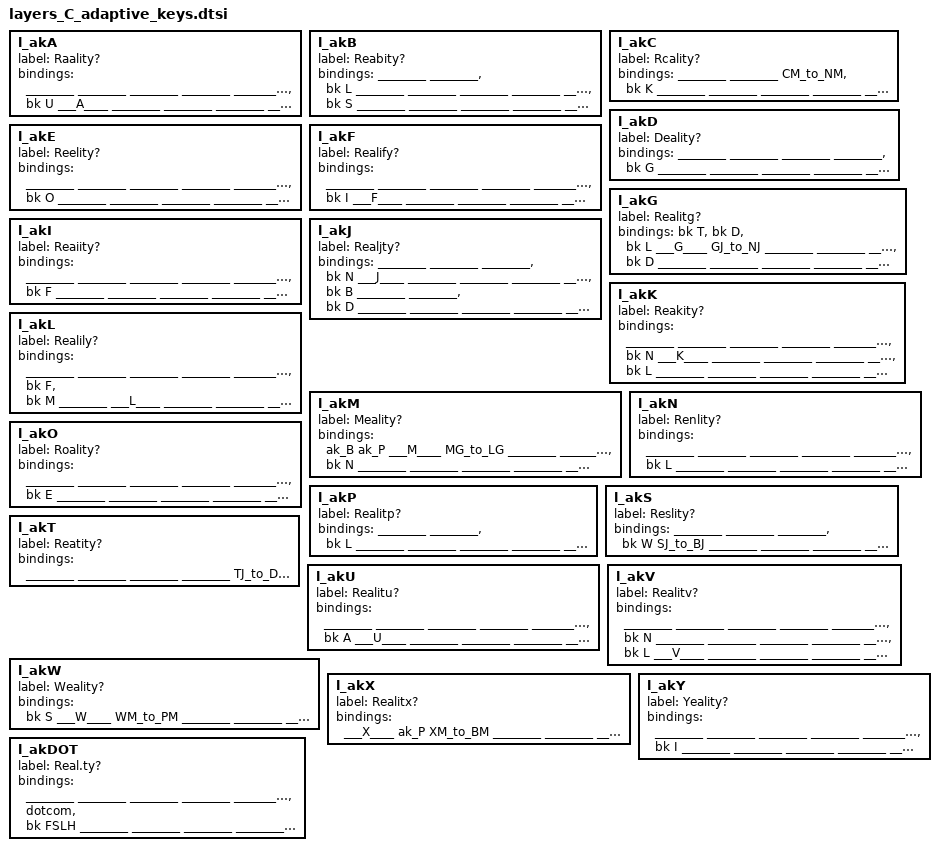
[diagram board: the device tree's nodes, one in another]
                l_akA {
                        label = "Raality?";
                        bindings = <
________   ________   ________   ________   ________          ________   ________   ________   ________   ________
________   ________   ________   ________   ________          &bk U      ___A____   ________   ________   ________
________   ________   ________   ________   ________          ________   ________   ________   ________   ________
                        ________   ________   ________      ________   ________   ________
                        >;
                };

                l_akB {
                        label = "Reabity?";
                        bindings = <
________   ________   &bk L      ________   ________          ________   ________   ________   ________   ________ /* 'L' is for the M->B->L sequence */
________   ________   ________   ________   ________          ________   ________   ________   ________   ________
___B____   &bk S      ________   ________   ________          ________   ________   ________   ________   ________
                        ________   ________   ________      ________   ________   ________
                        >;
                };

                l_akC {
                        label = "Rcality?";
                        bindings = <
________   ________   CM_to_NM   &bk K      ________          ________   ________   ________   ________   ________
________   ___C____   ________   ________   ________          ________   ________   ________   ________   ________
________   ________   ________   ________   ________          ________   ________   ________   ________   ________
                        ________   ________   ________      ________   ________   ________
                        >;
                };

                l_akD {
                        label = "Deality?";
                        bindings = <
________   ________   ________   ________   &bk G             ________   ________   ________   ________   ________
________   ________   ________   ________   DK_to_LK          ________   ________   ________   ________   ________
________   ________   ________   ___D____   DV_to_LV          ________   ________   ________   ________   ________
                        ________   ________   ________      ________   ________   ________
                        >;
                };

                l_akE {
                        label = "Reelity?";
                        bindings = <
________   ________   ________   ________   ________          ________   ________   ________   ________   ________
________   ________   ________   ________   ________          ________   ________   ___E____   ________   &bk O
________   ________   ________   ________   ________          ________   ________   ________   ________   ________
                        ________   ________   ________      ________   ________   ________
                        >;
                };

                l_akF {
                        label = "Realify?";
                        bindings = <
________   ________   ________   ________   ________          ________   ________   ________   ________   ________
________   ________   ________   ________   ________          ________   ________   ________   ________   ________
________   ________   ________   ________   ________          ________   ________   ________   &bk I      ___F____
                        ________   ________   ________      ________   ________   ________
                        >;
                };

                l_akG {
                        label = "Realitg?";
                        bindings = <
&bk T      &bk D      &bk L      ___G____   GJ_to_NJ          ________   ________   ________   ________   ________
________   ________   ________   ________   ________          ________   ________   ________   ________   ________
________   ________   ________   ________   &bk D             ________   ________   ________   ________   ________
                        ________   ________   ________      ________   ________   ________
                        >;
                };

                l_akI {
                        label = "Reaiity?";
                        bindings = <
________   ________   ________   ________   ________          ________   ________   ________   ________   ________
________   ________   ________   ________   ________          ________   ________   ________   ___I____   &bk F
________   ________   ________   ________   ________          ________   ________   ________   ________   ________
                        ________   ________   ________      ________   ________   ________
                        >;
                };

                l_akJ {
                        label = "Realjty?";
                        bindings = <
/* NOTE
This AK layer is not really needed, but it is here for ensuring the symetry of the J key.
This makes the "replace_char_with_bigram_NJ/BJ" much more intuitive.
*/
________   ________   ________   &bk N      ___J____          ________   ________   ________   ________   ________
&bk B      ________   ________   &bk D      ________          ________   ________   ________   ________   ________
________   ________   ________   ________   ________          ________   ________   ________   ________   ________
                        ________   ________   ________      ________   ________   ________
                        >;
                };

                l_akK {
                        label = "Reakity?";
                        bindings = <
________   ________   ________   ________   ________          ________   ________   ________   ________   ________
________   ________   ________   &bk N      ___K____          ________   ________   ________   ________   ________
________   ________   ________   &bk L      ________          ________   ________   ________   ________   ________
                        ________   ________   ________      ________   ________   ________
                        >;
                };


                l_akL {
                        label = "Realily?";
                        bindings = <
________   ________   ________   ________   ________          ________   ________   ________   ________   ________
________   ________   ________   ________   ________          ________   ________   ________   ________   &bk F
&bk M      ________   ___L____   ________   ________          ________   ________   ________   ________   ________
                        ________   ________   ________      ________   ________   ________
                        >;
                };


                l_akM {
                        label = "Meality?";
                        bindings = <
ak_B       ak_P       ___M____   MG_to_LG   ________          ________   ________   ________   ________   ________
________   &bk N      ________   ________   ________          ________   ________   ________   ________   ________
________   ________   ________   ________   ________          ________   ________   ________   ________   ________
                        ________   ________   ________      ________   ________   ________
                        >;
                };

                l_akN {
                        label = "Renlity?";
                        bindings = <
________   ________   ________   ________   ________           ________   ________   ________   ________   ________
________   ________   ___N____   ________   ________           ________   ________   ________   ________   ________
________   &bk L      ________   ________   ________           ________   ________   ________   ________   ________
                        ________   ________   ________      ________   ________   ________
                        >;
                };

                l_akO {
                        label = "Roality?";
                        bindings = <
________   ________   ________   ________   ________          ________   ________   ________   ________   ________
________   ________   ________   ________   ________          ________   ________   ________   ________   &bk E
________   ________   ________   ________   ________          ________   ________   ___O____   ________   ________
                        ________   ________   ________      ________   ________   ________
                        >;
                };

                l_akP {
                        label = "Realitp?";
                        bindings = <
________   ________   &bk L      ________   ________          ________   ________   ________   ________   ________ /* 'L' is for the M->P->L and X->P->L sequences */
________   ________   PN_to_LN   ________   ________          ________   ________   ________   ________   ________
PB_to_SB   ___P____   ________   ________   ________          ________   ________   ________   ________   ________
                        ________   ________   ________      ________   ________   ________
                        >;
                };

                l_akS {
                        label = "Reslity?";
                        bindings = <
________   ________   ________   &bk W      SJ_to_BJ          ________   ________   ________   ________   ________
___S____   ________   ________   ________   ________          ________   ________   ________   ________   ________
________   ________   ________   ________   ________          ________   ________   ________   ________   ________
                        ________   ________   ________      ________   ________   ________
                        >;
                };

                l_akT {
                        label = "Reatity?";
                        bindings = <
________   ________   ________   ________   TJ_to_DJ          ________   ________   ________   ________   ________
________   ________   ________   ___T____   TK_to_NK          ________   ________   ________   ________   ________
________   ________   ________   ________   TV_to_NV          ________   ________   ________   ________   ________
                        ________   ________   ________      ________   ________   ________
                        >;
                };

                l_akU {
                        label = "Realitu?";
                        bindings = <
________   ________   ________   ________   ________          ________   ________   ________   ________   ________
________   ________   ________   ________   ________          ________   ________   ________   ________   ________
________   ________   ________   ________   ________          &bk A      ___U____   ________   ________   ________
                        ________   ________   ________      ________   ________   ________
                        >;
                };

                l_akV {
                        label = "Realitv?";
                        bindings = <
/* NOTE
This AK layer is not really needed, but it is here for ensuring the symetry of the V key.
This makes the following much more intuitive.
- TV_to_NV
- DV_to_LV
*/
________   ________   ________   ________   ________          ________   ________   ________   ________   ________
________   ________   ________   &bk N      ________          ________   ________   ________   ________   ________
________   ________   ________   &bk L      ___V____          ________   ________   ________   ________   ________
                        ________   ________   ________      ________   ________   ________
                        >;
                };


                l_akW {
                        label = "Weality?";
                        bindings = <
&bk S      ___W____   WM_to_PM   ________   ________          ________   ________   ________   ________   ________
________   ________   ________   ________   ________          ________   ________   ________   ________   ________
________   ________   ________   ________   ________          ________   ________   ________   ________   ________
                        ________   ________   ________      ________   ________   ________
                        >;
                };

                l_akX {
                        label = "Realitx?";
                        bindings = <
___X____   ak_P       XM_to_BM   ________   ________          ________   ________   ________   ________   ________
________   ________   ________   ________   ________          ________   ________   ________   ________   ________
________   ________   ________   ________   ________          ________   ________   ________   ________   ________
                        ________   ________   ________      ________   ________   ________
                        >;
                };

                l_akY {
                        label = "Yeality?";
                        bindings = <
________   ________   ________   ________   ________          ________   ________   ________   ________   ________
________   ________   ________   ________   ________          ________   ________   ________   ________   &bk I
________   ________   ________   ________   ________          ________   ________   ________   ___Y____   ________
                        ________   ________   ________      ________   ________   ________
                        >;
                };

// TODO: Fix 3 dots, include backspace before
#define _3_Dots_ &bk LA(SEMI)
                l_akDOT {
                        label = "Real.ty?";
                        bindings = <
________   ________   ________   ________   ________          ________   ________   _3_Dots_   &dotcom    &bk FSLH
________   ________   ________   ________   ________          ________   ________   ________   ________   ________
________   ________   ________   ________   ________          ________   ________   ________   ________   ________
                        ________   ________   ________      ________   ________   ________
                        >;
                };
